# TC37XPD register map
Vendor: Infineon; Series: ATVMC; File version: 100
CPU: other r0p0, little endian, MPU, FPU, vendor SysTick, 4 interrupt priority bits
Registers are 32-bit, read-write, reset 0x0 unless marked. A register's access mark holds for its fields unless they carry their own. Offsets are from the block's base; [hi:lo] are bit positions; lines under a group give offsets from that group; {n}, {i} and the like mark numbered series; 'fields as' and 'values as' point back to an identical list.

## GTM (part 12 of 13)
Base 0xF0100000
{0xF0000+0x1000*i} MCS[{i}] (i=0..4) group
  0x00 MCS0_CH0_R0 — MCS0 Channel 7 General Purpose Register 7 resetvalue={Application Reset:0x0}
    [23:0] DATA — Data of general purpose register R y . Note This register is the same as described in internal register section. Note For the register MCS i CH x R6 see internal register section an additional write protection during an active ARDI or NARDI instruction is applied
  0x04 MCS0_CH0_R1 — MCS0 Channel 7 General Purpose Register 7 resetvalue={Application Reset:0x0}
    fields as MCS[0].MCS0_CH0_R0
  0x08 MCS0_CH0_R2 — MCS0 Channel 7 General Purpose Register 7 resetvalue={Application Reset:0x0}
    fields as MCS[0].MCS0_CH0_R0
  0x0C MCS0_CH0_R3 — MCS0 Channel 7 General Purpose Register 7 resetvalue={Application Reset:0x0}
    fields as MCS[0].MCS0_CH0_R0
  0x10 MCS0_CH0_R4 — MCS0 Channel 7 General Purpose Register 7 resetvalue={Application Reset:0x0}
    fields as MCS[0].MCS0_CH0_R0
  0x14 MCS0_CH0_R5 — MCS0 Channel 7 General Purpose Register 7 resetvalue={Application Reset:0x0}
    fields as MCS[0].MCS0_CH0_R0
  0x18 MCS0_CH0_R6 — MCS0 Channel 7 General Purpose Register 7 resetvalue={Application Reset:0x0}
    fields as MCS[0].MCS0_CH0_R0
  0x1C MCS0_CH0_R7 — MCS0 Channel 7 General Purpose Register 7 resetvalue={Application Reset:0x0}
    fields as MCS[0].MCS0_CH0_R0
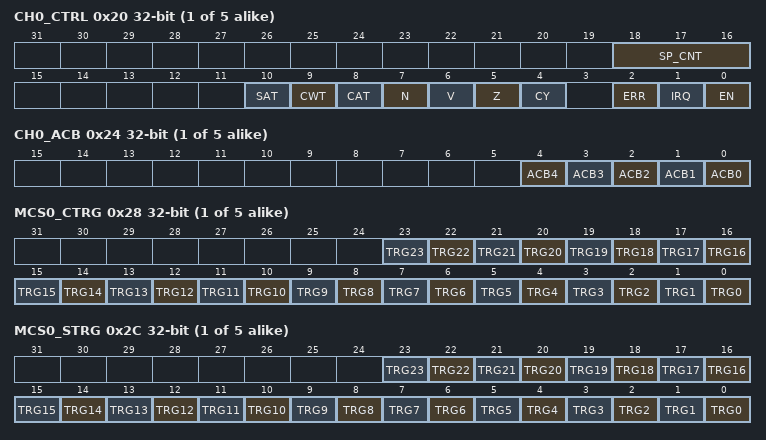
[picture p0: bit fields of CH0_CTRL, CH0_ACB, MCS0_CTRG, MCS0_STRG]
  0x20 CH0_CTRL access per field — MCS0 Channel 7 Control Register resetvalue={Application Reset:0x0}
    [18:16] SP_CNT ro — Stack pointer counter value. Actual stack depth of channel. The bit field is incremented on behalf of a CALL or PUSH instruction and decremented on behalf of a RET or POP instruction. The MCS channel STK ERR IRQ is raised when an overflow or underflow is detected on this bit field.
    [10] SAT ro — Successful ARU transfer bit. This bit is read only and it mirrors the internal state of the ARU transfer status flag SAT.
    [9] CWT ro — Cancel WURM instruction state. This bit is read only and it mirrors the internal cancel WURM instruction status flag CWT.
    [8] CAT ro — Cancel ARU transfer state. This bit is read only and it mirrors the internal cancel ARU transfer status flag CAT.
    [7] N ro — Negative bit state. This bit is read only and it mirrors the internal zero flag N.
    [6] V ro — Overflow bit state. This bit is read only and it mirrors the internal carry flag V.
    [5] Z ro — Zero bit state. This bit is read only and it mirrors the internal zero flag Z.
    [4] CY ro — Carry bit state. This bit is read only and it mirrors the internal carry flag CY.
    [2] ERR ro — Error state. This bit is read only and it mirrors the internal error state.
    [1] IRQ ro — Interrupt state. This bit is read only and it mirrors the internal IRQ state.
    [0] EN rw — Enable MCS channel. Note Enabling or disabling of an MCS channel is synchronized to the ending of an instruction and thus it may take several clock cycles e.g. active memory transfers or pending WURM transfers have to be finished before disabling the MCS channel. The internal state of a channel can be obtained by reading bit EN. Note To disable an MCS channel reliably the EN bit should be cleared followed by setting the CAT and CWT bits in order to cancel any pending WURM or ARU instructions. Note The EN bit is write protected during RAM reset phase.
  0x24 CH0_ACB ro — MCS0 Channel 7 ARU Control Bit Register resetvalue={Application Reset:0x0}
    [n] ACB{n} (n=0..4) — ARU Control bit {n}. This bit is read only and it mirrors the internal state.
  0x28 MCS0_CTRG — MCS0 Clear Trigger Control Register resetvalue={Application Reset:0x0}
    [n] TRG{n} (n=16..23) — Trigger bit 23
    [n] TRG{n} (n=8..15) — Trigger bit 15. READ access State of current trigger bit TRGk if EN TIM FOUT 0 State of input signal TIM i 1 CH k 8 F OUT if EN TIM FOUT 1 WRITE access
    [n] TRG{n} (n=0..7) — Trigger bit 7. READ access State of current trigger bit TRGk if EN TIM FOUT 0 State of input signal TIM i CH k F OUT if EN TIM FOUT 1 WRITE access
  0x2C MCS0_STRG — MCS0 Set Trigger Control Register resetvalue={Application Reset:0x0}
    [n] TRG{n} (n=0..23) — Trigger bit 23
  0x3C CH0_MHB ro — MCS0 Channel 7 Memory High Byte Register resetvalue={Application Reset:0x0}
    [7:0] DATA — Data of memory high bit register MHB
  0x40 CH0_PC reset 0x1C — MCS0 Channel 7 Program Counter Register resetvalue={Application Reset:0x1C}
    [15:0] PC — Current Program Counter. Note The program counter is only writable if the corresponding MCS channel is disabled. The bits 0 and 1 are always written as zeros. Note The actual width of the program counter depends on the MCS configuration. The actual width is RAW USR 2 bits meaning that only the bits 0 to RAW USR 1 are available and the other bits RAW USR 2 to 31 are reserved.
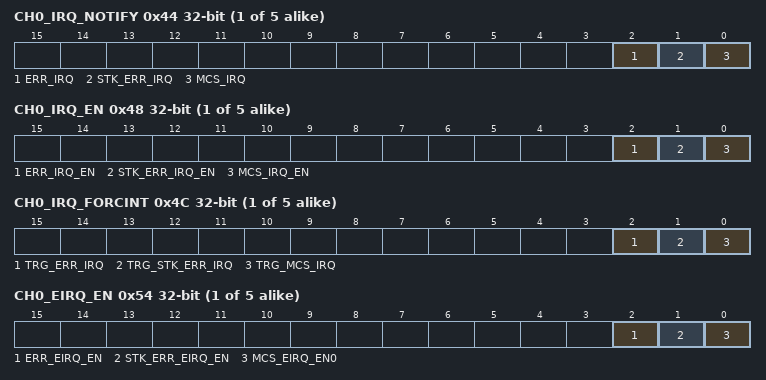
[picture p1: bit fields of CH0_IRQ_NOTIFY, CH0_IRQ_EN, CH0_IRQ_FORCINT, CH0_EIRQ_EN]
  0x44 CH0_IRQ_NOTIFY — MCS0 Channel 7 Interrupt Notification Register resetvalue={Application Reset:0x0}
    [2] ERR_IRQ — MCS channel x ERR interrupt. If the ERR bit of register STA is triggered the ERR IRQ will also be set. This bit will be cleared on a CPU write access with a value of 1 . A read access leaves the bit unchanged.
    [1] STK_ERR_IRQ — Stack counter overflow underflow of channel x. Note This bit will be cleared on a CPU write access with a value of 1 . A read access leaves the bit unchanged.
    [0] MCS_IRQ — Interrupt request by MCS channel x. This bit will be cleared on a CPU write access with a value of 1 . A read access leaves the bit unchanged. By writing a 1 to this register the IRQ flag in the MCS channel status register STA is cleared.
  0x48 CH0_IRQ_EN — MCS0 Channel 7 Interrupt Enable Register resetvalue={Application Reset:0x0}
    [2] ERR_IRQ_EN — MCS channel x ERR IRQ interrupt enable
    [1] STK_ERR_IRQ_EN — MCS channel x STK ERR IRQ interrupt enable
    [0] MCS_IRQ_EN — MCS channel x MCS IRQ interrupt enable
  0x4C CH0_IRQ_FORCINT — MCS0 Channel 7 Force Interrupt Register resetvalue={Application Reset:0x0}
    [2] TRG_ERR_IRQ — Trigger IRQ bit in MCS CH x IRQ NOTIFY register by software. This bit is cleared automatically after write. This bit is write protected by bit RF PROT of register GTM CTRL.
    [1] TRG_STK_ERR_IRQ — Trigger IRQ bit in MCS CH x IRQ NOTIFY register by software. This bit is cleared automatically after write. This bit is write protected by bit RF PROT of register GTM CTRL.
    [0] TRG_MCS_IRQ — Trigger IRQ bit in MCS CH x IRQ NOTIFY register by software. This bit is cleared automatically after write. This bit is write protected by bit RF PROT of register GTM CTRL.
  0x50 CH0_IRQ_MODE — MCS0 Channel 7 Interrupt Mode Configuration Register resetvalue={Application Reset:0x0}
    [1:0] IRQ_MODE — IRQ mode selection. The interrupt modes are described in CROSSREFERENCE .
  0x54 CH0_EIRQ_EN — MCS0 Channel 7 Error Interrupt Enable Register resetvalue={Application Reset:0x0}
    [2] ERR_EIRQ_EN — MCS channel x ERR EIRQ error interrupt enable
    [1] STK_ERR_EIRQ_EN — MCS channel x STK ERR IRQ error interrupt enable
    [0] MCS_EIRQ_EN0 — MCS channel x MCS EIRQ error interrupt enable
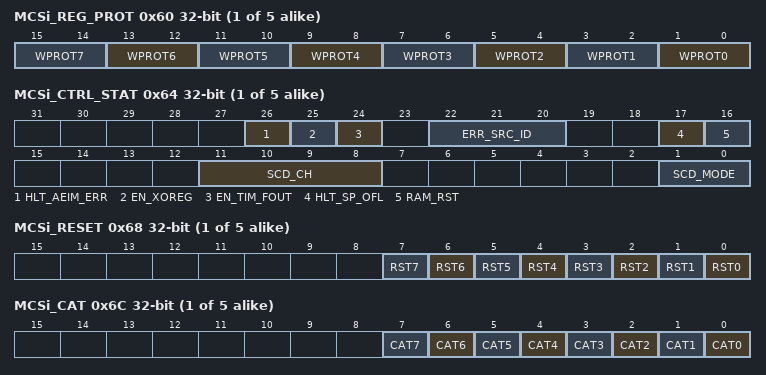
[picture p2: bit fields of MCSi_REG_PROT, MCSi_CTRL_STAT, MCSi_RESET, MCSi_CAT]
  0x60 MCSi_REG_PROT — MCS0 Write Protection Register resetvalue={Application Reset:0x0}
    [2n+1:2n] WPROT{n} (n=0..7) — Register Write Protection of MCS channel 7
  0x64 MCSi_CTRL_STAT access per field — MCS0 Control and Status Register resetvalue={Application Reset:0x0}
    [26] HLT_AEIM_ERR rw — Halt on AEI bus master error. If the register HLT AEIM ERR is set and an MCS channel x is executing an invalid bus master access the MCS channel x is halted the ERR bit of its register STA is set and the bit field ERR SRC ID of this register is updated. If the bus master is accessing a slave that does not insert wait cycles e.g. register access it takes two additional clock cycles until the MCS channel is halted. Within that time span the MCS channel can continue with its program execution depending on the selected scheduling mode. The registers AEIM XPT STA and AEIM XPT ADDR of the GTM sub module CCM are always updated on the first invalid AEI bus master access independently of the state of HLT AEIM ERR
    [25] EN_XOREG rw — Enable extended register set. Note If the extended operation register sets are disabled the MCS instructions can only use the subset OREG of the register set as arguments in the instructions. In this case the upper address bits in the instructions are always read as zeros which leads to unexpected results of the MCS program if arguments A or B refer to a register that is not part of OREG .
    [24] EN_TIM_FOUT rw — Enable routing of TIM i CH x F OUT signal
    [22:20] ERR_SRC_ID ro — Error source identifier. This register is updated once if an error was detected by the MCS. The register is set to its initial value 000 after each write access to an existing ERR bit in register MCS i ERR. If multiple errors occur ERR SRC ID is holding the first type of error which has occurred.
    [17] HLT_SP_OFL rw — Halt on stack pointer overflow
    [16] RAM_RST rw — RAM reset bit. The RAM reset initializes the memory content with zeros. RAM access and enabling of MCS channels is disabled during active RAM reset. This bit is only writable if the bit RF PROT in register GTM CTRL is cleared and all MCS channels are disabled. The actual reset value of this bit depends on the silicon vendor configuration. The reset value is 1 if the RAM reset is performed together with the sub module reset otherwise the reset value is 0. If the reset value is 1 the reset value is changed to 0 by hardware when the RAM reset has finished.
    [11:8] SCD_CH rw — Channel selection for scheduling algorithm. MCS channel identifier used by several scheduling modes. The actual width of the bit field SCD CH is calculated as ceiling log 2 T 1 . Unused MSBs are reserved and read as zero.
    [1:0] SCD_MODE rw — Select MCS scheduling mode
  0x68 MCSi_RESET — MCS0 Reset Register resetvalue={Application Reset:0x0}
    [n] RST{n} (n=0..7) — Software reset of channel 7
  0x6C MCSi_CAT — MCS0 Cancel ARU Transfer Instruction Register resetvalue={Application Reset:0x0}
    [n] CAT{n} (n=0..7) — Cancel ARU transfer for channel 7. The CATx x 0..T 1 bit inside the STA register of the corresponding MCS channel is set and any pending blocking ARU read or write request is canceled. The MCS channel resumes with the instruction after the blocking ARU transfer instruction. The CATx x 0..T 1 bit is cleared by the corresponding MCS channel when the channel is entering a blocking ARU read or write instruction.
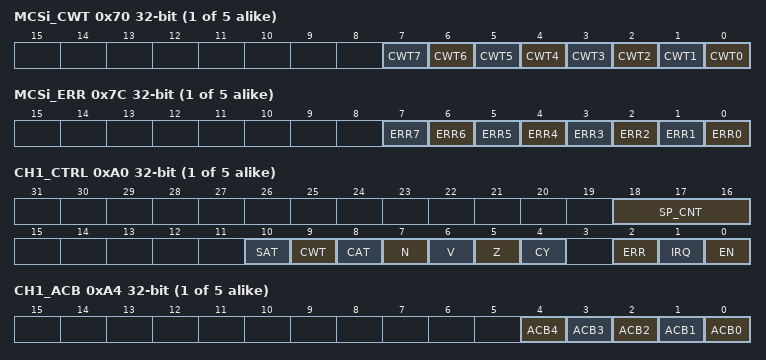
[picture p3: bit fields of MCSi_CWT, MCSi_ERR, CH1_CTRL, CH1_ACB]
  0x70 MCSi_CWT — MCS0 Cancel WURM Instruction Register resetvalue={Application Reset:0x0}
    [n] CWT{n} (n=0..7) — Cancel WURM instruction for channel 7. The CWTx x 0..T 1 bit inside the STA register of the corresponding MCS channel is set and any pending WURM instruction is canceled. The MC channel resumes with the instruction after the WURM instruction. The CWTx x 0..T 1 bit is cleared by the corresponding MCS channel when the channel reaches a WURM instruction.
  0x7C MCSi_ERR — MCS0 error register resetvalue={Application Reset:0x0}
    [n] ERR{n} (n=0..7) — Error State of MCS channel 7. The CPU can read the ERRx x 0..T 1 bits in order to determine the current error state of the corresponding MCS channel x. The error state is also evaluated by the sub module MON if this module is available. Writing the value 1 to this bit resets the corresponding error state and resets the channel internal ERR bit in the STA and channel CTRL registers. Moreover each write access to this bit also sets the ERR SRC ID bit field of register MCS i CTRL STAT to its reset value.
  0x80 MCS0_CH1_R0 — MCS0 Channel 7 General Purpose Register 7 resetvalue={Application Reset:0x0}
    fields as MCS[0].MCS0_CH0_R0
  0x84 MCS0_CH1_R1 — MCS0 Channel 7 General Purpose Register 7 resetvalue={Application Reset:0x0}
    fields as MCS[0].MCS0_CH0_R0
  0x88 MCS0_CH1_R2 — MCS0 Channel 7 General Purpose Register 7 resetvalue={Application Reset:0x0}
    fields as MCS[0].MCS0_CH0_R0
  0x8C MCS0_CH1_R3 — MCS0 Channel 7 General Purpose Register 7 resetvalue={Application Reset:0x0}
    fields as MCS[0].MCS0_CH0_R0
  0x90 MCS0_CH1_R4 — MCS0 Channel 7 General Purpose Register 7 resetvalue={Application Reset:0x0}
    fields as MCS[0].MCS0_CH0_R0
  0x94 MCS0_CH1_R5 — MCS0 Channel 7 General Purpose Register 7 resetvalue={Application Reset:0x0}
    fields as MCS[0].MCS0_CH0_R0
  0x98 MCS0_CH1_R6 — MCS0 Channel 7 General Purpose Register 7 resetvalue={Application Reset:0x0}
    fields as MCS[0].MCS0_CH0_R0
  0x9C MCS0_CH1_R7 — MCS0 Channel 7 General Purpose Register 7 resetvalue={Application Reset:0x0}
    fields as MCS[0].MCS0_CH0_R0
  0xA0 CH1_CTRL access per field — MCS0 Channel 7 Control Register resetvalue={Application Reset:0x0}
    fields as MCS[0].CH0_CTRL
  0xA4 CH1_ACB ro — MCS0 Channel 7 ARU Control Bit Register resetvalue={Application Reset:0x0}
    fields as MCS[0].CH0_ACB
  0xBC CH1_MHB ro — MCS0 Channel 7 Memory High Byte Register resetvalue={Application Reset:0x0}
    [7:0] DATA — Data of memory high bit register MHB
  0xC0 CH1_PC reset 0x1C — MCS0 Channel 7 Program Counter Register resetvalue={Application Reset:0x1C}
    fields as MCS[0].CH0_PC
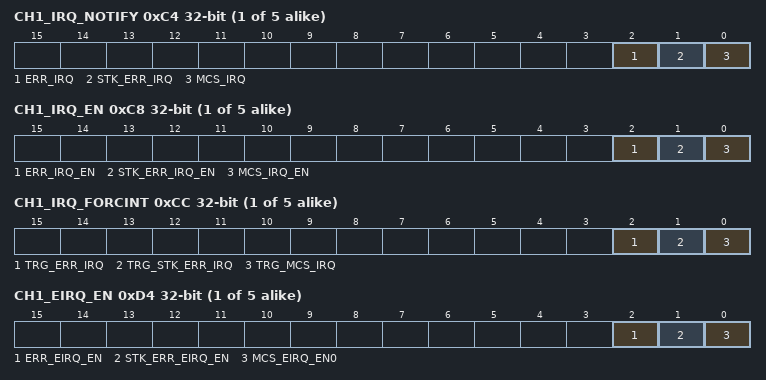
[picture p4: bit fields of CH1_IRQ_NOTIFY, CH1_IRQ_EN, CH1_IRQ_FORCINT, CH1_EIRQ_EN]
  0xC4 CH1_IRQ_NOTIFY — MCS0 Channel 7 Interrupt Notification Register resetvalue={Application Reset:0x0}
    fields as MCS[0].CH0_IRQ_NOTIFY
  0xC8 CH1_IRQ_EN — MCS0 Channel 7 Interrupt Enable Register resetvalue={Application Reset:0x0}
    fields as MCS[0].CH0_IRQ_EN
  0xCC CH1_IRQ_FORCINT — MCS0 Channel 7 Force Interrupt Register resetvalue={Application Reset:0x0}
    fields as MCS[0].CH0_IRQ_FORCINT
  0xD0 CH1_IRQ_MODE — MCS0 Channel 7 Interrupt Mode Configuration Register resetvalue={Application Reset:0x0}
    fields as MCS[0].CH0_IRQ_MODE
  0xD4 CH1_EIRQ_EN — MCS0 Channel 7 Error Interrupt Enable Register resetvalue={Application Reset:0x0}
    fields as MCS[0].CH0_EIRQ_EN
  0x100 MCS0_CH2_R0 — MCS0 Channel 7 General Purpose Register 7 resetvalue={Application Reset:0x0}
    fields as MCS[0].MCS0_CH0_R0
  0x104 MCS0_CH2_R1 — MCS0 Channel 7 General Purpose Register 7 resetvalue={Application Reset:0x0}
    fields as MCS[0].MCS0_CH0_R0
  0x108 MCS0_CH2_R2 — MCS0 Channel 7 General Purpose Register 7 resetvalue={Application Reset:0x0}
    fields as MCS[0].MCS0_CH0_R0
  0x10C MCS0_CH2_R3 — MCS0 Channel 7 General Purpose Register 7 resetvalue={Application Reset:0x0}
    fields as MCS[0].MCS0_CH0_R0
  0x110 MCS0_CH2_R4 — MCS0 Channel 7 General Purpose Register 7 resetvalue={Application Reset:0x0}
    fields as MCS[0].MCS0_CH0_R0
  0x114 MCS0_CH2_R5 — MCS0 Channel 7 General Purpose Register 7 resetvalue={Application Reset:0x0}
    fields as MCS[0].MCS0_CH0_R0
  0x118 MCS0_CH2_R6 — MCS0 Channel 7 General Purpose Register 7 resetvalue={Application Reset:0x0}
    fields as MCS[0].MCS0_CH0_R0
  0x11C MCS0_CH2_R7 — MCS0 Channel 7 General Purpose Register 7 resetvalue={Application Reset:0x0}
    fields as MCS[0].MCS0_CH0_R0
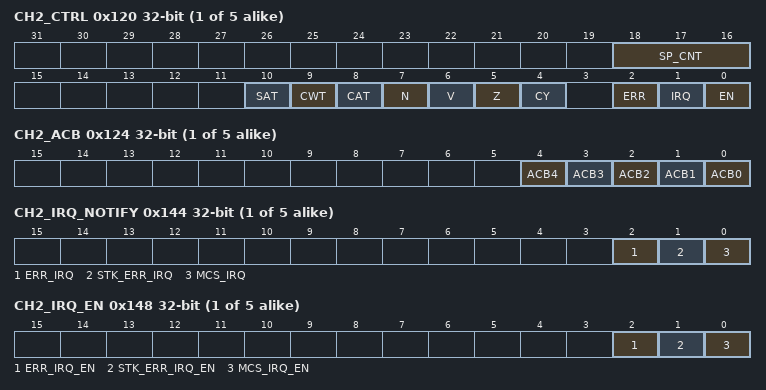
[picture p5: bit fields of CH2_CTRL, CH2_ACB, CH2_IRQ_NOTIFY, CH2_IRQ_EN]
  0x120 CH2_CTRL access per field — MCS0 Channel 7 Control Register resetvalue={Application Reset:0x0}
    fields as MCS[0].CH0_CTRL
  0x124 CH2_ACB ro — MCS0 Channel 7 ARU Control Bit Register resetvalue={Application Reset:0x0}
    fields as MCS[0].CH0_ACB
  0x13C CH2_MHB ro — MCS0 Channel 7 Memory High Byte Register resetvalue={Application Reset:0x0}
    [7:0] DATA — Data of memory high bit register MHB
  0x140 CH2_PC reset 0x1C — MCS0 Channel 7 Program Counter Register resetvalue={Application Reset:0x1C}
    fields as MCS[0].CH0_PC
  0x144 CH2_IRQ_NOTIFY — MCS0 Channel 7 Interrupt Notification Register resetvalue={Application Reset:0x0}
    fields as MCS[0].CH0_IRQ_NOTIFY
  0x148 CH2_IRQ_EN — MCS0 Channel 7 Interrupt Enable Register resetvalue={Application Reset:0x0}
    fields as MCS[0].CH0_IRQ_EN
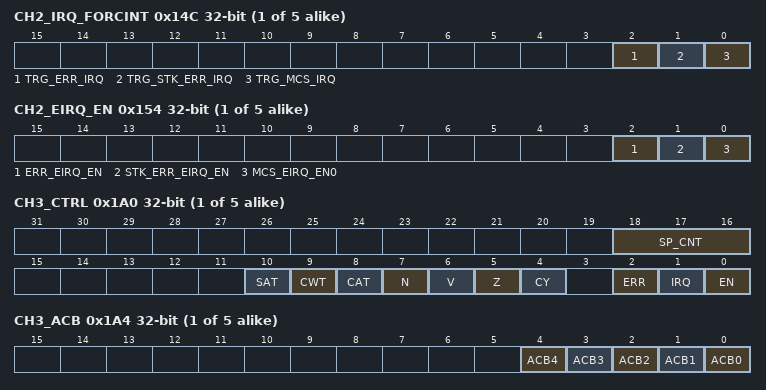
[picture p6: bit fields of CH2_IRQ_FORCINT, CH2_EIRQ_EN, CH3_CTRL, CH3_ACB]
  0x14C CH2_IRQ_FORCINT — MCS0 Channel 7 Force Interrupt Register resetvalue={Application Reset:0x0}
    fields as MCS[0].CH0_IRQ_FORCINT
  0x150 CH2_IRQ_MODE — MCS0 Channel 7 Interrupt Mode Configuration Register resetvalue={Application Reset:0x0}
    fields as MCS[0].CH0_IRQ_MODE
  0x154 CH2_EIRQ_EN — MCS0 Channel 7 Error Interrupt Enable Register resetvalue={Application Reset:0x0}
    fields as MCS[0].CH0_EIRQ_EN
  0x180 MCS0_CH3_R0 — MCS0 Channel 7 General Purpose Register 7 resetvalue={Application Reset:0x0}
    fields as MCS[0].MCS0_CH0_R0
  0x184 MCS0_CH3_R1 — MCS0 Channel 7 General Purpose Register 7 resetvalue={Application Reset:0x0}
    fields as MCS[0].MCS0_CH0_R0
  0x188 MCS0_CH3_R2 — MCS0 Channel 7 General Purpose Register 7 resetvalue={Application Reset:0x0}
    fields as MCS[0].MCS0_CH0_R0
  0x18C MCS0_CH3_R3 — MCS0 Channel 7 General Purpose Register 7 resetvalue={Application Reset:0x0}
    fields as MCS[0].MCS0_CH0_R0
  0x190 MCS0_CH3_R4 — MCS0 Channel 7 General Purpose Register 7 resetvalue={Application Reset:0x0}
    fields as MCS[0].MCS0_CH0_R0
  0x194 MCS0_CH3_R5 — MCS0 Channel 7 General Purpose Register 7 resetvalue={Application Reset:0x0}
    fields as MCS[0].MCS0_CH0_R0
  0x198 MCS0_CH3_R6 — MCS0 Channel 7 General Purpose Register 7 resetvalue={Application Reset:0x0}
    fields as MCS[0].MCS0_CH0_R0
  0x19C MCS0_CH3_R7 — MCS0 Channel 7 General Purpose Register 7 resetvalue={Application Reset:0x0}
    fields as MCS[0].MCS0_CH0_R0
  0x1A0 CH3_CTRL access per field — MCS0 Channel 7 Control Register resetvalue={Application Reset:0x0}
    fields as MCS[0].CH0_CTRL
  0x1A4 CH3_ACB ro — MCS0 Channel 7 ARU Control Bit Register resetvalue={Application Reset:0x0}
    fields as MCS[0].CH0_ACB
  0x1BC CH3_MHB ro — MCS0 Channel 7 Memory High Byte Register resetvalue={Application Reset:0x0}
    [7:0] DATA — Data of memory high bit register MHB
  0x1C0 CH3_PC reset 0x1C — MCS0 Channel 7 Program Counter Register resetvalue={Application Reset:0x1C}
    fields as MCS[0].CH0_PC
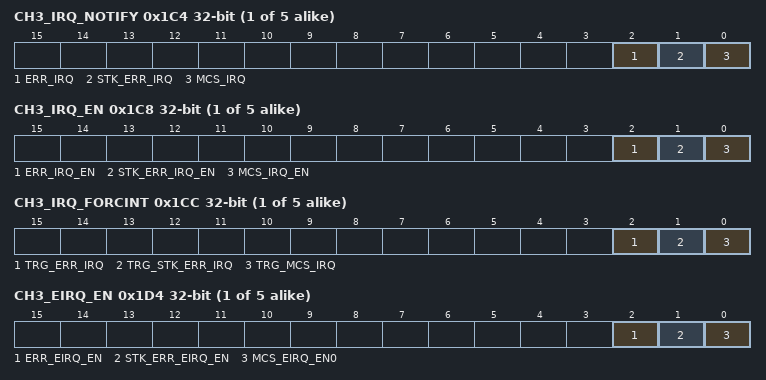
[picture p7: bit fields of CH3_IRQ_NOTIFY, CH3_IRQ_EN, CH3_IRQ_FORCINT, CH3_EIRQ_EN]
  0x1C4 CH3_IRQ_NOTIFY — MCS0 Channel 7 Interrupt Notification Register resetvalue={Application Reset:0x0}
    fields as MCS[0].CH0_IRQ_NOTIFY
  0x1C8 CH3_IRQ_EN — MCS0 Channel 7 Interrupt Enable Register resetvalue={Application Reset:0x0}
    fields as MCS[0].CH0_IRQ_EN
  0x1CC CH3_IRQ_FORCINT — MCS0 Channel 7 Force Interrupt Register resetvalue={Application Reset:0x0}
    fields as MCS[0].CH0_IRQ_FORCINT
  0x1D0 CH3_IRQ_MODE — MCS0 Channel 7 Interrupt Mode Configuration Register resetvalue={Application Reset:0x0}
    fields as MCS[0].CH0_IRQ_MODE
  0x1D4 CH3_EIRQ_EN — MCS0 Channel 7 Error Interrupt Enable Register resetvalue={Application Reset:0x0}
    fields as MCS[0].CH0_EIRQ_EN
  0x200 MCS0_CH4_R0 — MCS0 Channel 7 General Purpose Register 7 resetvalue={Application Reset:0x0}
    fields as MCS[0].MCS0_CH0_R0
  0x204 MCS0_CH4_R1 — MCS0 Channel 7 General Purpose Register 7 resetvalue={Application Reset:0x0}
    fields as MCS[0].MCS0_CH0_R0
  0x208 MCS0_CH4_R2 — MCS0 Channel 7 General Purpose Register 7 resetvalue={Application Reset:0x0}
    fields as MCS[0].MCS0_CH0_R0
  0x20C MCS0_CH4_R3 — MCS0 Channel 7 General Purpose Register 7 resetvalue={Application Reset:0x0}
    fields as MCS[0].MCS0_CH0_R0
  0x210 MCS0_CH4_R4 — MCS0 Channel 7 General Purpose Register 7 resetvalue={Application Reset:0x0}
    fields as MCS[0].MCS0_CH0_R0
  0x214 MCS0_CH4_R5 — MCS0 Channel 7 General Purpose Register 7 resetvalue={Application Reset:0x0}
    fields as MCS[0].MCS0_CH0_R0
  0x218 MCS0_CH4_R6 — MCS0 Channel 7 General Purpose Register 7 resetvalue={Application Reset:0x0}
    fields as MCS[0].MCS0_CH0_R0
  0x21C MCS0_CH4_R7 — MCS0 Channel 7 General Purpose Register 7 resetvalue={Application Reset:0x0}
    fields as MCS[0].MCS0_CH0_R0
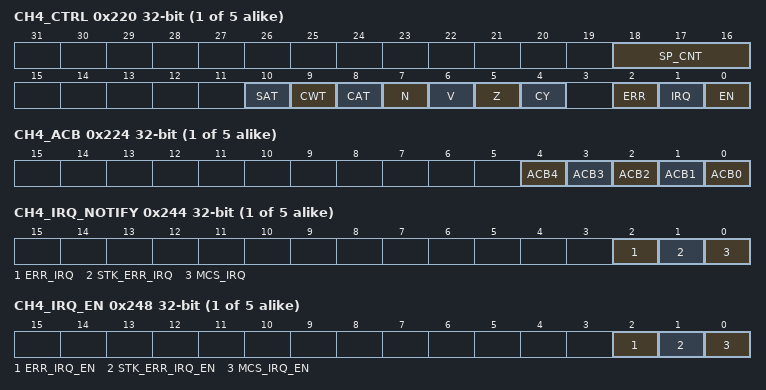
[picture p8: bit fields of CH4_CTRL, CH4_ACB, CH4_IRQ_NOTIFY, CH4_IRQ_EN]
  0x220 CH4_CTRL access per field — MCS0 Channel 7 Control Register resetvalue={Application Reset:0x0}
    fields as MCS[0].CH0_CTRL
  0x224 CH4_ACB ro — MCS0 Channel 7 ARU Control Bit Register resetvalue={Application Reset:0x0}
    fields as MCS[0].CH0_ACB
  0x23C CH4_MHB ro — MCS0 Channel 7 Memory High Byte Register resetvalue={Application Reset:0x0}
    [7:0] DATA — Data of memory high bit register MHB
  0x240 CH4_PC reset 0x1C — MCS0 Channel 7 Program Counter Register resetvalue={Application Reset:0x1C}
    fields as MCS[0].CH0_PC
  0x244 CH4_IRQ_NOTIFY — MCS0 Channel 7 Interrupt Notification Register resetvalue={Application Reset:0x0}
    fields as MCS[0].CH0_IRQ_NOTIFY
  0x248 CH4_IRQ_EN — MCS0 Channel 7 Interrupt Enable Register resetvalue={Application Reset:0x0}
    fields as MCS[0].CH0_IRQ_EN
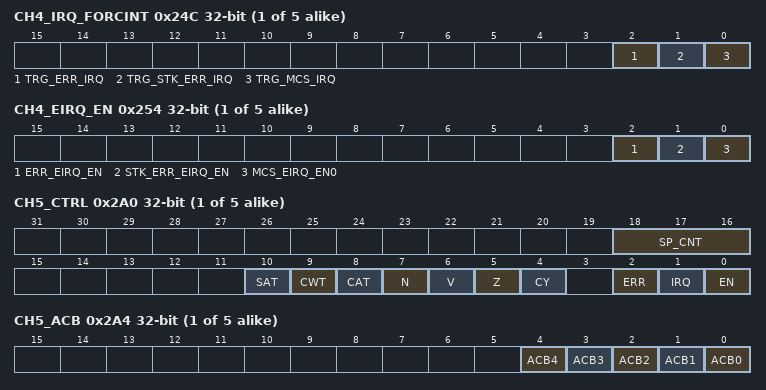
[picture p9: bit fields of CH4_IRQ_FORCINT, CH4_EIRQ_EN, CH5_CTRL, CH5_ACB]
  0x24C CH4_IRQ_FORCINT — MCS0 Channel 7 Force Interrupt Register resetvalue={Application Reset:0x0}
    fields as MCS[0].CH0_IRQ_FORCINT
  0x250 CH4_IRQ_MODE — MCS0 Channel 7 Interrupt Mode Configuration Register resetvalue={Application Reset:0x0}
    fields as MCS[0].CH0_IRQ_MODE
  0x254 CH4_EIRQ_EN — MCS0 Channel 7 Error Interrupt Enable Register resetvalue={Application Reset:0x0}
    fields as MCS[0].CH0_EIRQ_EN
  0x280 MCS0_CH5_R0 — MCS0 Channel 7 General Purpose Register 7 resetvalue={Application Reset:0x0}
    fields as MCS[0].MCS0_CH0_R0
  0x284 MCS0_CH5_R1 — MCS0 Channel 7 General Purpose Register 7 resetvalue={Application Reset:0x0}
    fields as MCS[0].MCS0_CH0_R0
  0x288 MCS0_CH5_R2 — MCS0 Channel 7 General Purpose Register 7 resetvalue={Application Reset:0x0}
    fields as MCS[0].MCS0_CH0_R0
  0x28C MCS0_CH5_R3 — MCS0 Channel 7 General Purpose Register 7 resetvalue={Application Reset:0x0}
    fields as MCS[0].MCS0_CH0_R0
  0x290 MCS0_CH5_R4 — MCS0 Channel 7 General Purpose Register 7 resetvalue={Application Reset:0x0}
    fields as MCS[0].MCS0_CH0_R0
  0x294 MCS0_CH5_R5 — MCS0 Channel 7 General Purpose Register 7 resetvalue={Application Reset:0x0}
    fields as MCS[0].MCS0_CH0_R0
  0x298 MCS0_CH5_R6 — MCS0 Channel 7 General Purpose Register 7 resetvalue={Application Reset:0x0}
    fields as MCS[0].MCS0_CH0_R0
  0x29C MCS0_CH5_R7 — MCS0 Channel 7 General Purpose Register 7 resetvalue={Application Reset:0x0}
    fields as MCS[0].MCS0_CH0_R0
  0x2A0 CH5_CTRL access per field — MCS0 Channel 7 Control Register resetvalue={Application Reset:0x0}
    fields as MCS[0].CH0_CTRL
  0x2A4 CH5_ACB ro — MCS0 Channel 7 ARU Control Bit Register resetvalue={Application Reset:0x0}
    fields as MCS[0].CH0_ACB
  0x2BC CH5_MHB ro — MCS0 Channel 7 Memory High Byte Register resetvalue={Application Reset:0x0}
    [7:0] DATA — Data of memory high bit register MHB
  0x2C0 CH5_PC reset 0x1C — MCS0 Channel 7 Program Counter Register resetvalue={Application Reset:0x1C}
    fields as MCS[0].CH0_PC
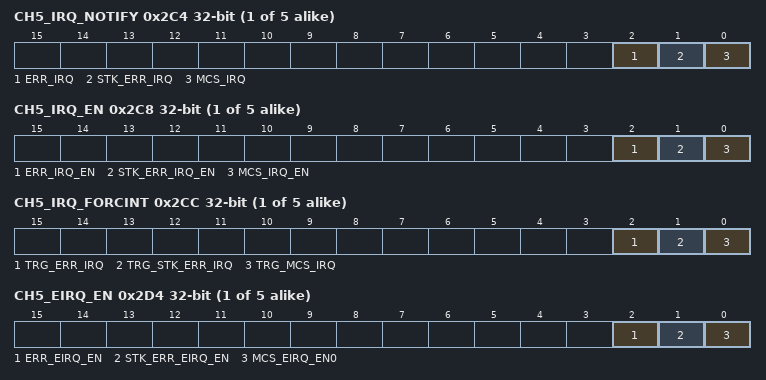
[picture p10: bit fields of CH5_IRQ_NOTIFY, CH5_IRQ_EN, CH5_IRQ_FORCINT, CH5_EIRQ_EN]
  0x2C4 CH5_IRQ_NOTIFY — MCS0 Channel 7 Interrupt Notification Register resetvalue={Application Reset:0x0}
    fields as MCS[0].CH0_IRQ_NOTIFY
  0x2C8 CH5_IRQ_EN — MCS0 Channel 7 Interrupt Enable Register resetvalue={Application Reset:0x0}
    fields as MCS[0].CH0_IRQ_EN
  0x2CC CH5_IRQ_FORCINT — MCS0 Channel 7 Force Interrupt Register resetvalue={Application Reset:0x0}
    fields as MCS[0].CH0_IRQ_FORCINT
  0x2D0 CH5_IRQ_MODE — MCS0 Channel 7 Interrupt Mode Configuration Register resetvalue={Application Reset:0x0}
    fields as MCS[0].CH0_IRQ_MODE
  0x2D4 CH5_EIRQ_EN — MCS0 Channel 7 Error Interrupt Enable Register resetvalue={Application Reset:0x0}
    fields as MCS[0].CH0_EIRQ_EN
  0x300 MCS0_CH6_R0 — MCS0 Channel 7 General Purpose Register 7 resetvalue={Application Reset:0x0}
    fields as MCS[0].MCS0_CH0_R0
  0x304 MCS0_CH6_R1 — MCS0 Channel 7 General Purpose Register 7 resetvalue={Application Reset:0x0}
    fields as MCS[0].MCS0_CH0_R0
  0x308 MCS0_CH6_R2 — MCS0 Channel 7 General Purpose Register 7 resetvalue={Application Reset:0x0}
    fields as MCS[0].MCS0_CH0_R0
  0x30C MCS0_CH6_R3 — MCS0 Channel 7 General Purpose Register 7 resetvalue={Application Reset:0x0}
    fields as MCS[0].MCS0_CH0_R0
  0x310 MCS0_CH6_R4 — MCS0 Channel 7 General Purpose Register 7 resetvalue={Application Reset:0x0}
    fields as MCS[0].MCS0_CH0_R0
  0x314 MCS0_CH6_R5 — MCS0 Channel 7 General Purpose Register 7 resetvalue={Application Reset:0x0}
    fields as MCS[0].MCS0_CH0_R0
  0x318 MCS0_CH6_R6 — MCS0 Channel 7 General Purpose Register 7 resetvalue={Application Reset:0x0}
    fields as MCS[0].MCS0_CH0_R0
  0x31C MCS0_CH6_R7 — MCS0 Channel 7 General Purpose Register 7 resetvalue={Application Reset:0x0}
    fields as MCS[0].MCS0_CH0_R0
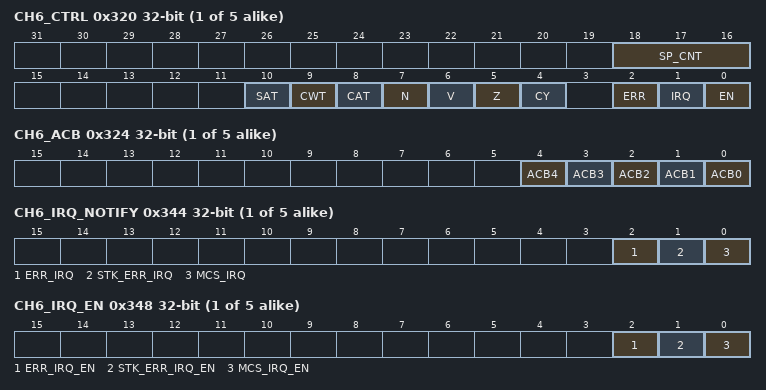
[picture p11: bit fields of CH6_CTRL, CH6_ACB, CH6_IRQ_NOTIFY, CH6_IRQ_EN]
  0x320 CH6_CTRL access per field — MCS0 Channel 7 Control Register resetvalue={Application Reset:0x0}
    fields as MCS[0].CH0_CTRL
  0x324 CH6_ACB ro — MCS0 Channel 7 ARU Control Bit Register resetvalue={Application Reset:0x0}
    fields as MCS[0].CH0_ACB
  0x33C CH6_MHB ro — MCS0 Channel 7 Memory High Byte Register resetvalue={Application Reset:0x0}
    [7:0] DATA — Data of memory high bit register MHB
  0x340 CH6_PC reset 0x1C — MCS0 Channel 7 Program Counter Register resetvalue={Application Reset:0x1C}
    fields as MCS[0].CH0_PC
  0x344 CH6_IRQ_NOTIFY — MCS0 Channel 7 Interrupt Notification Register resetvalue={Application Reset:0x0}
    fields as MCS[0].CH0_IRQ_NOTIFY
  0x348 CH6_IRQ_EN — MCS0 Channel 7 Interrupt Enable Register resetvalue={Application Reset:0x0}
    fields as MCS[0].CH0_IRQ_EN
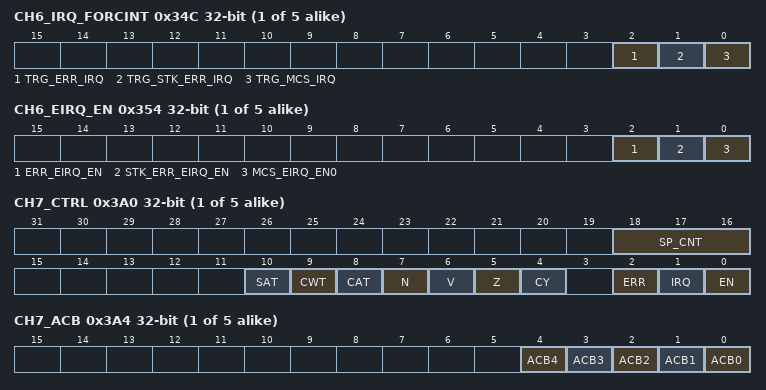
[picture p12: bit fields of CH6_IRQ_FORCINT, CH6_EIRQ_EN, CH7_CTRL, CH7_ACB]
  0x34C CH6_IRQ_FORCINT — MCS0 Channel 7 Force Interrupt Register resetvalue={Application Reset:0x0}
    fields as MCS[0].CH0_IRQ_FORCINT
  0x350 CH6_IRQ_MODE — MCS0 Channel 7 Interrupt Mode Configuration Register resetvalue={Application Reset:0x0}
    fields as MCS[0].CH0_IRQ_MODE
  0x354 CH6_EIRQ_EN — MCS0 Channel 7 Error Interrupt Enable Register resetvalue={Application Reset:0x0}
    fields as MCS[0].CH0_EIRQ_EN
  0x380 MCS0_CH7_R0 — MCS0 Channel 7 General Purpose Register 7 resetvalue={Application Reset:0x0}
    fields as MCS[0].MCS0_CH0_R0
  0x384 MCS0_CH7_R1 — MCS0 Channel 7 General Purpose Register 7 resetvalue={Application Reset:0x0}
    fields as MCS[0].MCS0_CH0_R0
  0x388 MCS0_CH7_R2 — MCS0 Channel 7 General Purpose Register 7 resetvalue={Application Reset:0x0}
    fields as MCS[0].MCS0_CH0_R0
  0x38C MCS0_CH7_R3 — MCS0 Channel 7 General Purpose Register 7 resetvalue={Application Reset:0x0}
    fields as MCS[0].MCS0_CH0_R0
  0x390 MCS0_CH7_R4 — MCS0 Channel 7 General Purpose Register 7 resetvalue={Application Reset:0x0}
    fields as MCS[0].MCS0_CH0_R0
  0x394 MCS0_CH7_R5 — MCS0 Channel 7 General Purpose Register 7 resetvalue={Application Reset:0x0}
    fields as MCS[0].MCS0_CH0_R0
  0x398 MCS0_CH7_R6 — MCS0 Channel 7 General Purpose Register 7 resetvalue={Application Reset:0x0}
    fields as MCS[0].MCS0_CH0_R0
  0x39C MCS0_CH7_R7 — MCS0 Channel 7 General Purpose Register 7 resetvalue={Application Reset:0x0}
    fields as MCS[0].MCS0_CH0_R0
  0x3A0 CH7_CTRL access per field — MCS0 Channel 7 Control Register resetvalue={Application Reset:0x0}
    fields as MCS[0].CH0_CTRL
  0x3A4 CH7_ACB ro — MCS0 Channel 7 ARU Control Bit Register resetvalue={Application Reset:0x0}
    fields as MCS[0].CH0_ACB
  0x3BC CH7_MHB ro — MCS0 Channel 7 Memory High Byte Register resetvalue={Application Reset:0x0}
    [7:0] DATA — Data of memory high bit register MHB
  0x3C0 CH7_PC reset 0x1C — MCS0 Channel 7 Program Counter Register resetvalue={Application Reset:0x1C}
    fields as MCS[0].CH0_PC
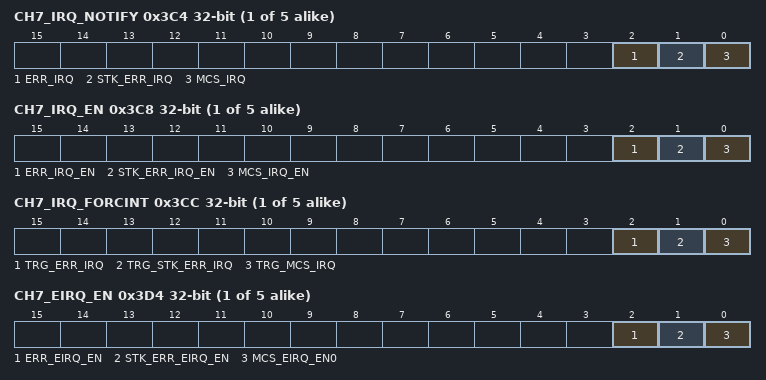
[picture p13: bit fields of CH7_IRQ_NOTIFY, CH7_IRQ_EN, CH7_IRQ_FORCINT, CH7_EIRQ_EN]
  0x3C4 CH7_IRQ_NOTIFY — MCS0 Channel 7 Interrupt Notification Register resetvalue={Application Reset:0x0}
    fields as MCS[0].CH0_IRQ_NOTIFY
  0x3C8 CH7_IRQ_EN — MCS0 Channel 7 Interrupt Enable Register resetvalue={Application Reset:0x0}
    fields as MCS[0].CH0_IRQ_EN
  0x3CC CH7_IRQ_FORCINT — MCS0 Channel 7 Force Interrupt Register resetvalue={Application Reset:0x0}
    fields as MCS[0].CH0_IRQ_FORCINT
  0x3D0 CH7_IRQ_MODE — MCS0 Channel 7 Interrupt Mode Configuration Register resetvalue={Application Reset:0x0}
    fields as MCS[0].CH0_IRQ_MODE
  0x3D4 CH7_EIRQ_EN — MCS0 Channel 7 Error Interrupt Enable Register resetvalue={Application Reset:0x0}
    fields as MCS[0].CH0_EIRQ_EN
